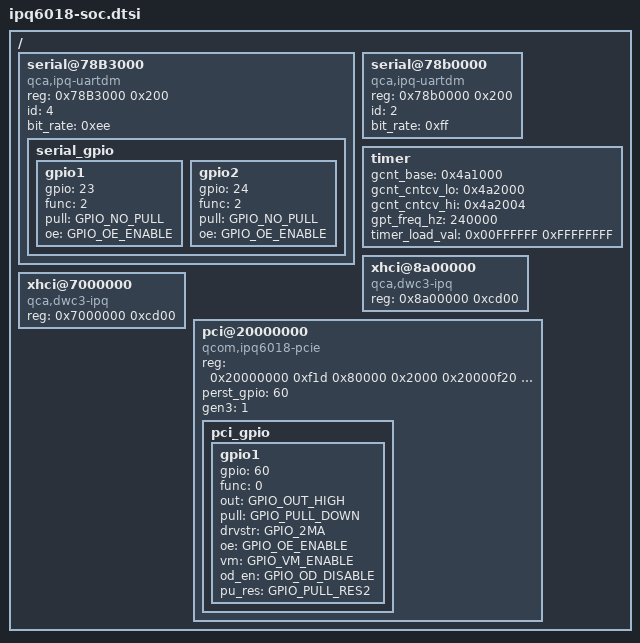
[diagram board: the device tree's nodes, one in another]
/*
 * Copyright (c) 2016-2018, The Linux Foundation. All rights reserved.
 *
 * This program is free software; you can redistribute it and/or modify
 * it under the terms of the GNU General Public License version 2 and
 * only version 2 as published by the Free Software Foundation.
 *
 * This program is distributed in the hope that it will be useful,
 * but WITHOUT ANY WARRANTY; without even the implied warranty of
 * MERCHANTABILITY or FITNESS FOR A PARTICULAR PURPOSE.  See the
 * GNU General Public License for more details.
 */

#include "skeleton.dtsi"
#include <dt-bindings/qcom/gpio-ipq6018.h>

/ {

	serial@78B3000 {
		compatible = "qca,ipq-uartdm";
		reg = <0x78B3000 0x200>;
		id = <4>;
		bit_rate = <0xee>;
		serial_gpio {
			gpio1 {
				gpio = <23>;
				func = <2>;
				pull = <GPIO_NO_PULL>;
				oe = <GPIO_OE_ENABLE>;
			};

			gpio2 {
				gpio = <24>;
				func = <2>;
				pull = <GPIO_NO_PULL>;
				oe = <GPIO_OE_ENABLE>;
			};
		};
	};
	serial@78b0000 {
		compatible = "qca,ipq-uartdm";
		reg = <0x78b0000 0x200>;
		id = <2>;
		bit_rate = <0xff>;
	};

	timer {
		gcnt_base = <0x4a1000>;
		gcnt_cntcv_lo = <0x4a2000>;
		gcnt_cntcv_hi = <0x4a2004>;
		gpt_freq_hz = <240000>;
		timer_load_val = <0x00FFFFFF 0xFFFFFFFF>;
	};

	xhci@8a00000 {
		compatible = "qca,dwc3-ipq";
		#address-cells = <1>;
		#size-cells = <1>;
		reg = <0x8a00000 0xcd00>;
	};

	xhci@7000000 {
		compatible = "qca,dwc3-ipq";
		#address-cells = <1>;
		#size-cells = <1>;
		reg = <0x7000000 0xcd00>;
	};

	pci@20000000 {
		compatible = "qcom,ipq6018-pcie";
		#address-cells = <1>;
		#size-cells = <1>;
		reg = <0x20000000 0xf1d
			0x80000 0x2000
			0x20000f20 0xa8
			0x20001000 0x1000
			0x20300000 0xd00000
			0x20100000 0x100000
			0x01875004 0x40
			0x84000 0x1000>;
		reg-names = "pci_dbi", "parf", "elbi","dm_iatu", "axi_bars",
				"axi_conf", "pci_rst", "pci_phy";
		perst_gpio = <60>;
		gen3 = <1>;

		pci_gpio {
			gpio1 {
				gpio = <60>;
				func = <0>;
				out = <GPIO_OUT_HIGH>;
				pull = <GPIO_PULL_DOWN>;
				drvstr = <GPIO_2MA>;
				oe = <GPIO_OE_ENABLE>;
				vm = <GPIO_VM_ENABLE>;
				od_en = <GPIO_OD_DISABLE>;
				pu_res = <GPIO_PULL_RES2>;
			};

		};
	};

};

